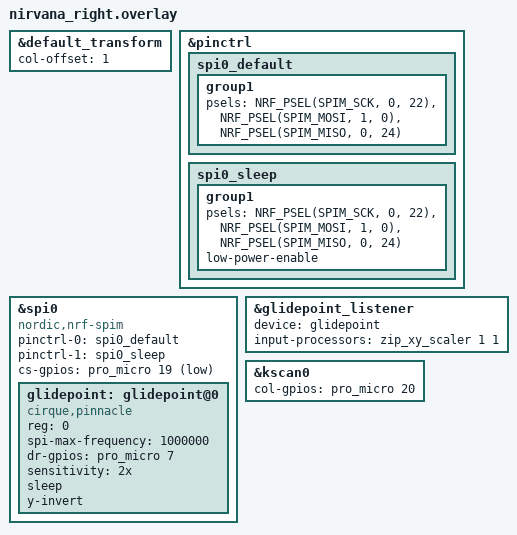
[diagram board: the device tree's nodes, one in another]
#include "nirvana.dtsi"
#include <dt-bindings/zmk/input_transform.h>
#include <input/processors.dtsi>
#include <zephyr/dt-bindings/input/input-event-codes.h>

&default_transform {
    col-offset = <1>;
};

&pinctrl {
    /* configuration for spi0 device, default state */
    spi0_default: spi0_default {
        /* node name is arbitrary */
        group1 {
            psels = <NRF_PSEL(SPIM_SCK, 0, 22)>,
                    <NRF_PSEL(SPIM_MOSI, 1, 0)>,
                    <NRF_PSEL(SPIM_MISO, 0, 24)>;
        };
    };

    /* configuration for spi0 device, sleep state */
    spi0_sleep: spi0_sleep {
        group1 {
            psels = <NRF_PSEL(SPIM_SCK, 0, 22)>,
                    <NRF_PSEL(SPIM_MOSI, 1, 0)>,
                    <NRF_PSEL(SPIM_MISO, 0, 24)>;
            low-power-enable;
        };
    };

};

&spi0 {
    compatible = "nordic,nrf-spim";
    pinctrl-0 = <&spi0_default>;
    pinctrl-1 = <&spi0_sleep>;
    pinctrl-names = "default", "sleep";

    status = "okay";

    cs-gpios = <&pro_micro 19 GPIO_ACTIVE_LOW>;
    glidepoint: glidepoint@0 {
        compatible = "cirque,pinnacle";
        reg = <0>;
        spi-max-frequency = <1000000>;
        status = "okay";
        dr-gpios = <&pro_micro 7 (GPIO_ACTIVE_HIGH)>;

        sensitivity = "2x";
        sleep;
        y-invert;
        //no-taps;
    };
};

// Overrides for the input listener node
&glidepoint_listener {
    status = "okay";
    device = <&glidepoint>;
    input-processors = <&zip_xy_scaler 1 1>;
};

// 配置右边的kscan GPIO
// 根据你的实际硬件接线修改这些引脚
&kscan0 {
    col-gpios
        = <&pro_micro 20 GPIO_ACTIVE_HIGH>
        ;
};
